# MB9BF52xT register map
File version: 1.0
CPU: 
Registers are 8-bit, read-write, reset 0x0 unless marked. A register's access mark holds for its fields unless they carry their own. Offsets are from the block's base; [hi:lo] are bit positions; {n}, {i} and the like mark numbered series.

## CRTRIM — peripheral CRTRIM
Base 0x4002E000
0x00 MCR_PSR reset 0x1
  [1:0] CSR
0x04 MCR_FTRM 16-bit reset 0x200
  [9:0] TRD
0x08 MCR_TTRM reset 0xF
  [4:0] TRT
0x0C MCR_RLR 32-bit reset 0x1
  [31:0] TRMLCK

## SWWDT — peripheral SWWDT
Base 0x40012000
0x00 WDOGLOAD 32-bit reset 0xFFFFFFFF
0x04 WDOGVALUE 32-bit ro reset 0xFFFFFFFF
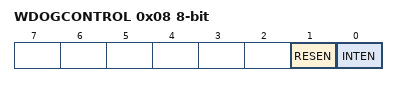
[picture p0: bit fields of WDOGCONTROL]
0x08 WDOGCONTROL
  [1] RESEN, [0] INTEN
0x0C WDOGINTCLR 32-bit reset 0xFFFFFFFF
0x10 WDOGRIS ro
  [0] RIS
0xC00 WDOGLOCK 32-bit

## HWWDT — peripheral HWWDT
Base 0x40011000
0x00 WDG_LDR 32-bit reset 0xFFFF
0x04 WDG_VLR 32-bit ro
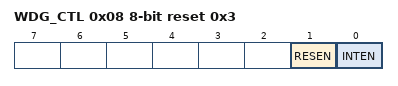
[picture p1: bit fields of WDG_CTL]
0x08 WDG_CTL reset 0x3
  [1] RESEN, [0] INTEN
0x0C WDG_ICL reset 0xFF (reset mask 0x0)
0x10 WDG_RIS ro reset 0xFF (reset mask 0x0)
  [0] RIS
0xC00 WDG_LCK 32-bit reset 0x1

## DTIM — peripheral DTIM
Base 0x40015000
0x00 TIMER1LOAD 32-bit (DualTimer1 view)
0x04 TIMER1VALUE 32-bit ro reset 0xFFFFFFFF
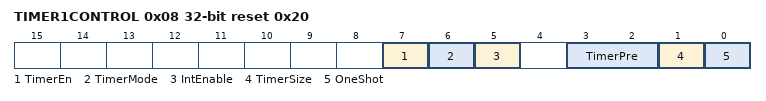
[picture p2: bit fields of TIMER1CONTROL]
0x08 TIMER1CONTROL 32-bit reset 0x20
  [7] TimerEn, [6] TimerMode, [5] IntEnable, [3:2] TimerPre, [1] TimerSize, [0] OneShot
0x0C TIMER1INTCLR 32-bit wo reset not defined
0x10 TIMER1RIS 32-bit ro
  [0] TIMER1RIS
0x14 TIMER1MIS 32-bit ro
  [0] TIMER1MIS
0x18 TIMER1BGLOAD 32-bit
0x20 TIMER2LOAD 32-bit reset not defined
0x24 TIMER2VALUE 32-bit reset not defined
0x28 TIMER2CONTROL 32-bit reset not defined
0x2C TIMER2INTCLR 32-bit reset not defined
0x30 TIMER2RIS 32-bit reset not defined
0x34 TIMER2MIS 32-bit reset not defined
0x38 TIMER2BGLOAD 32-bit reset not defined

## MFT0 — peripheral MFT0
Base 0x40020000
0x00 OCU_OCCP0 16-bit
{0x0+4i} OCU_OCCP{i} 32-bit reset not defined (i=1..5)
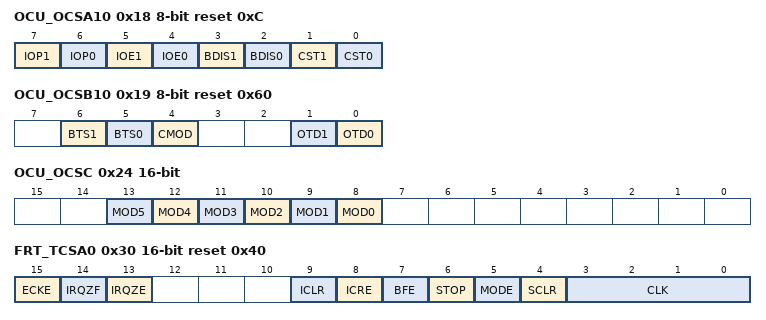
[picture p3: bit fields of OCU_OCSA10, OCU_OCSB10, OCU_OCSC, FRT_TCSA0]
0x18 OCU_OCSA10 reset 0xC
  [7] IOP1, [6] IOP0, [5] IOE1, [4] IOE0, [3] BDIS1, [2] BDIS0, [1] CST1, [0] CST0
0x19 OCU_OCSB10 reset 0x60
  [6] BTS1, [5] BTS0, [4] CMOD, [1] OTD1, [0] OTD0
0x1C OCU_OCSA32 32-bit reset not defined
0x1D OCU_OCSB32 32-bit reset not defined
0x20 OCU_OCSA54 32-bit reset not defined
0x21 OCU_OCSB54 32-bit reset not defined
0x24 OCU_OCSC 16-bit
  [n+8] MOD{n} (n=0..5)
0x28 FRT_TCCP0 16-bit reset 0xFFFF
0x2C FRT_TCDT0 16-bit
0x30 FRT_TCSA0 16-bit reset 0x40
  [15] ECKE, [14] IRQZF, [13] IRQZE, [9] ICLR, [8] ICRE, [7] BFE, [6] STOP, [5] MODE, [4] SCLR wo, [3:0] CLK
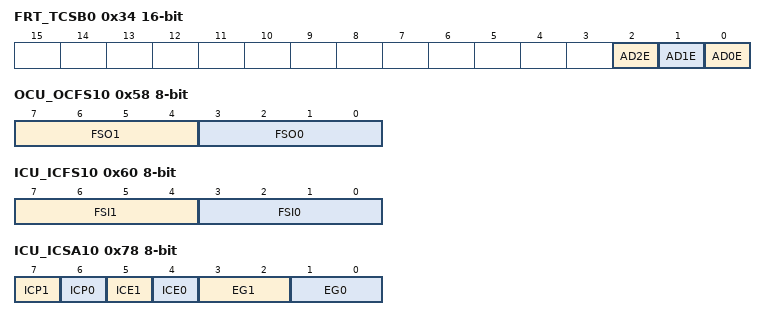
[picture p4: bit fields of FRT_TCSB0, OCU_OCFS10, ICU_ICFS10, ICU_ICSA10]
0x34 FRT_TCSB0 16-bit
  [2] AD2E, [1] AD1E, [0] AD0E
0x38 FRT_TCCP1 32-bit reset not defined
0x3C FRT_TCDT1 32-bit reset not defined
0x40 FRT_TCSA1 32-bit reset not defined
0x44 FRT_TCSB1 32-bit reset not defined
0x48 FRT_TCCP2 32-bit reset not defined
0x4C FRT_TCDT2 32-bit reset not defined
0x50 FRT_TCSA2 32-bit reset not defined
0x54 FRT_TCSB2 32-bit reset not defined
0x58 OCU_OCFS10
  [7:4] FSO1, [3:0] FSO0
0x59 OCU_OCFS32 32-bit reset not defined
0x5C OCU_OCFS54 32-bit reset not defined
0x60 ICU_ICFS10
  [7:4] FSI1, [3:0] FSI0
0x61 ICU_ICFS32 32-bit reset not defined
0x68 ICU_ICCP0 16-bit ro reset not defined
{0x68+4i} ICU_ICCP{i} 32-bit reset not defined (i=1..3)
0x78 ICU_ICSA10
  [7] ICP1, [6] ICP0, [5] ICE1, [4] ICE0, [3:2] EG1, [1:0] EG0
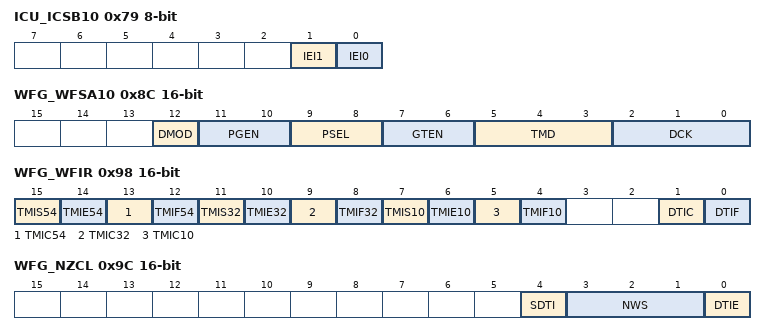
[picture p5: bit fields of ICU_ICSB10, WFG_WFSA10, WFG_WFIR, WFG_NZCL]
0x79 ICU_ICSB10 ro
  [1] IEI1, [0] IEI0
0x7C ICU_ICSA32 32-bit reset not defined
0x7D ICU_ICSB32 32-bit reset not defined
0x80 WFG_WFTM10 16-bit
0x84 WFG_WFTM32 32-bit reset not defined
0x88 WFG_WFTM54 32-bit reset not defined
0x8C WFG_WFSA10 16-bit
  [12] DMOD, [11:10] PGEN, [9:8] PSEL, [7:6] GTEN, [5:3] TMD, [2:0] DCK
0x90 WFG_WFSA32 32-bit reset not defined
0x94 WFG_WFSA54 32-bit reset not defined
0x98 WFG_WFIR 16-bit
  [15] TMIS54 wo, [14] TMIE54, [13] TMIC54 wo, [12] TMIF54 ro, [11] TMIS32 wo, [10] TMIE32, [9] TMIC32 wo, [8] TMIF32 ro, [7] TMIS10 wo, [6] TMIE10, [5] TMIC10 wo, [4] TMIF10 ro, [1] DTIC wo, [0] DTIF ro
0x9C WFG_NZCL 16-bit
  [4] SDTI wo, [3:1] NWS, [0] DTIE
0xA0 ADCMP_ACCP0 16-bit
0xA4 ADCMP_ACCPDN0 16-bit
0xA8 ADCMP_ACCP1 32-bit reset not defined
0xAC ADCMP_ACCPDN1 32-bit reset not defined
0xB0 ADCMP_ACCP2 32-bit reset not defined
0xB4 ADCMP_ACCPDN2 32-bit reset not defined
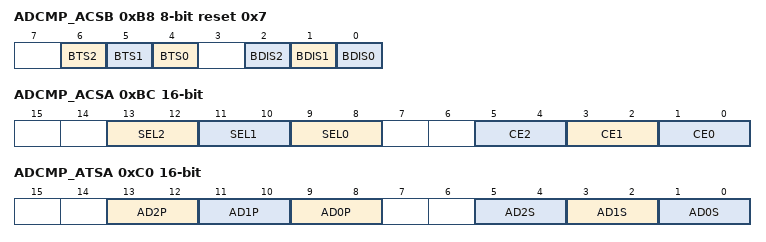
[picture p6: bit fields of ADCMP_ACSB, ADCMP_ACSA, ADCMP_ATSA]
0xB8 ADCMP_ACSB reset 0x7
  [6] BTS2, [5] BTS1, [4] BTS0, [2] BDIS2, [1] BDIS1, [0] BDIS0
0xBC ADCMP_ACSA 16-bit
  [13:12] SEL2, [11:10] SEL1, [9:8] SEL0, [5:4] CE2, [3:2] CE1, [1:0] CE0
0xC0 ADCMP_ATSA 16-bit
  [13:12] AD2P, [11:10] AD1P, [9:8] AD0P, [5:4] AD2S, [3:2] AD1S, [1:0] AD0S
